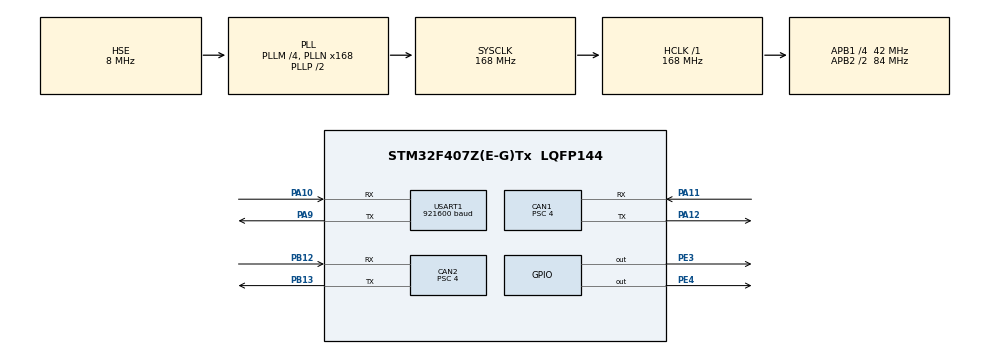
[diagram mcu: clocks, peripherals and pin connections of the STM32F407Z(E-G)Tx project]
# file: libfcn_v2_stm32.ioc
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CAN1.BS1=CAN_BS1_6TQ
CAN1.BS2=CAN_BS2_7TQ
CAN1.CalculateTimeQuantum=95.23809523809524
CAN1.Prescaler=4
CAN1.SJW=CAN_SJW_1TQ
CAN2.BS1=CAN_BS1_6TQ
CAN2.BS2=CAN_BS2_7TQ
CAN2.CalculateTimeQuantum=95.23809523809524
CAN2.Prescaler=4
Mcu.Family=STM32F4
Mcu.Name=STM32F407Z(E-G)Tx
Mcu.Package=LQFP144
NVIC.PriorityGroup=NVIC_PRIORITYGROUP_4
NVIC.TIM2_IRQn=true\:0\:0\:false\:false\:true\:false\:true
NVIC.TimeBase=TIM2_IRQn
NVIC.TimeBaseIP=TIM2
PA10.Mode=Asynchronous
PA10.Signal=USART1_RX
PA11.Mode=Master
PA11.Signal=CAN1_RX
PA12.Mode=Master
PA12.Signal=CAN1_TX
PA9.Mode=Asynchronous
PA9.Signal=USART1_TX
PB12.Mode=Slave
PB12.Signal=CAN2_RX
PB13.Mode=Slave
PB13.Signal=CAN2_TX
PC14-OSC32_IN.Mode=LSE-External-Oscillator
PC14-OSC32_IN.Signal=RCC_OSC32_IN
PC15-OSC32_OUT.Mode=LSE-External-Oscillator
PC15-OSC32_OUT.Signal=RCC_OSC32_OUT
PE3.GPIO_Speed=GPIO_SPEED_FREQ_VERY_HIGH
PE3.Signal=GPIO_Output
PE4.GPIO_Speed=GPIO_SPEED_FREQ_VERY_HIGH
PE4.Signal=GPIO_Output
PH0-OSC_IN.Mode=HSE-External-Oscillator
PH0-OSC_IN.Signal=RCC_OSC_IN
PH1-OSC_OUT.Mode=HSE-External-Oscillator
PH1-OSC_OUT.Signal=RCC_OSC_OUT
ProjectManager.HeapSize=0x200
ProjectManager.StackSize=0x400
ProjectManager.TargetToolchain=STM32CubeIDE
RCC.48MHZClocksFreq_Value=48000000
RCC.AHBFreq_Value=168000000
RCC.APB1CLKDivider=RCC_HCLK_DIV4
RCC.APB1Freq_Value=42000000
RCC.APB1TimFreq_Value=84000000
RCC.APB2CLKDivider=RCC_HCLK_DIV2
RCC.APB2Freq_Value=84000000
RCC.APB2TimFreq_Value=168000000
RCC.CortexFreq_Value=168000000
RCC.HCLKFreq_Value=168000000
RCC.HSE_VALUE=8000000
RCC.HSI_VALUE=16000000
RCC.PLLM=4
RCC.PLLN=168
RCC.PLLQ=7
RCC.PLLSourceVirtual=RCC_PLLSOURCE_HSE
RCC.SYSCLKFreq_VALUE=168000000
RCC.SYSCLKSource=RCC_SYSCLKSOURCE_PLLCLK
RCC.VCOOutputFreq_Value=336000000
USART1.BaudRate=921600
USART1.VirtualMode=VM_ASYNC
VP_CRC_VS_CRC.Mode=CRC_Activate
VP_RNG_VS_RNG.Mode=RNG_Activate
VP_SYS_VS_tim2.Mode=TIM2
board=custom

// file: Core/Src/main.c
/* USER CODE BEGIN Header */
/**
  ******************************************************************************
  * @file           : main.c
  * @brief          : Main program body
  ******************************************************************************
  * @attention
  *
  * <h2><center>&copy; Copyright (c) 2020 STMicroelectronics.
  * All rights reserved.</center></h2>
  *
  * This software component is licensed by ST under BSD 3-Clause license,
  * the "License"; You may not use this file except in compliance with the
  * License. You may obtain a copy of the License at:
  *                        opensource.org/licenses/BSD-3-Clause
  *
  ******************************************************************************
  */
/* USER CODE END Header */
#include "main.h"

/* USER CODE BEGIN Includes */
#include "../../User/UserTask.h"
/* USER CODE END Includes */

CAN_HandleTypeDef hcan1;
CAN_HandleTypeDef hcan2;

CRC_HandleTypeDef hcrc;

RNG_HandleTypeDef hrng;

UART_HandleTypeDef huart1;

void SystemClock_Config(void);
static void MX_GPIO_Init(void);
static void MX_USART1_UART_Init(void);
static void MX_CAN1_Init(void);
static void MX_CAN2_Init(void);
static void MX_CRC_Init(void);
static void MX_RNG_Init(void);

int main(void)
{

  /* MCU Configuration--------------------------------------------------------*/

  /* Reset of all peripherals, Initializes the Flash interface and the Systick. */
  HAL_Init();

  /* Configure the system clock */
  SystemClock_Config();

  /* Initialize all configured peripherals */
  MX_GPIO_Init();
  MX_USART1_UART_Init();
  MX_CAN1_Init();
  MX_CAN2_Init();
  MX_CRC_Init();
  MX_RNG_Init();
  /* USER CODE BEGIN 2 */
  BootTaskAfterHwInit();
  /* USER CODE END 2 */

  /* Infinite loop */
  while (1)
  {

    /* USER CODE BEGIN 3 */
	  MainLoopTask();
  }
  /* USER CODE END 3 */
}

void SystemClock_Config(void)
{
  RCC_OscInitTypeDef RCC_OscInitStruct = {0};
  RCC_ClkInitTypeDef RCC_ClkInitStruct = {0};

  /** Configure the main internal regulator output voltage
  */
  __HAL_RCC_PWR_CLK_ENABLE();
  __HAL_PWR_VOLTAGESCALING_CONFIG(PWR_REGULATOR_VOLTAGE_SCALE1);
  /** Initializes the RCC Oscillators according to the specified parameters
  * in the RCC_OscInitTypeDef structure.
  */
  RCC_OscInitStruct.OscillatorType = RCC_OSCILLATORTYPE_HSE;
  RCC_OscInitStruct.HSEState = RCC_HSE_ON;
  RCC_OscInitStruct.PLL.PLLState = RCC_PLL_ON;
  RCC_OscInitStruct.PLL.PLLSource = RCC_PLLSOURCE_HSE;
  RCC_OscInitStruct.PLL.PLLM = 4;
  RCC_OscInitStruct.PLL.PLLN = 168;
  RCC_OscInitStruct.PLL.PLLP = RCC_PLLP_DIV2;
  RCC_OscInitStruct.PLL.PLLQ = 7;
  if (HAL_RCC_OscConfig(&RCC_OscInitStruct) != HAL_OK)
  {
    Error_Handler();
  }
  /** Initializes the CPU, AHB and APB buses clocks
  */
  RCC_ClkInitStruct.ClockType = RCC_CLOCKTYPE_HCLK|RCC_CLOCKTYPE_SYSCLK
                              |RCC_CLOCKTYPE_PCLK1|RCC_CLOCKTYPE_PCLK2;
  RCC_ClkInitStruct.SYSCLKSource = RCC_SYSCLKSOURCE_PLLCLK;
  RCC_ClkInitStruct.AHBCLKDivider = RCC_SYSCLK_DIV1;
  RCC_ClkInitStruct.APB1CLKDivider = RCC_HCLK_DIV4;
  RCC_ClkInitStruct.APB2CLKDivider = RCC_HCLK_DIV2;

  if (HAL_RCC_ClockConfig(&RCC_ClkInitStruct, FLASH_LATENCY_5) != HAL_OK)
  {
    Error_Handler();
  }
}

static void MX_CAN1_Init(void)
{

  hcan1.Instance = CAN1;
  hcan1.Init.Prescaler = 4;
  hcan1.Init.Mode = CAN_MODE_NORMAL;
  hcan1.Init.SyncJumpWidth = CAN_SJW_1TQ;
  hcan1.Init.TimeSeg1 = CAN_BS1_6TQ;
  hcan1.Init.TimeSeg2 = CAN_BS2_7TQ;
  hcan1.Init.TimeTriggeredMode = DISABLE;
  hcan1.Init.AutoBusOff = DISABLE;
  hcan1.Init.AutoWakeUp = DISABLE;
  hcan1.Init.AutoRetransmission = DISABLE;
  hcan1.Init.ReceiveFifoLocked = DISABLE;
  hcan1.Init.TransmitFifoPriority = DISABLE;
  if (HAL_CAN_Init(&hcan1) != HAL_OK)
  {
    Error_Handler();
  }

}

static void MX_CAN2_Init(void)
{

  hcan2.Instance = CAN2;
  hcan2.Init.Prescaler = 4;
  hcan2.Init.Mode = CAN_MODE_NORMAL;
  hcan2.Init.SyncJumpWidth = CAN_SJW_1TQ;
  hcan2.Init.TimeSeg1 = CAN_BS1_6TQ;
  hcan2.Init.TimeSeg2 = CAN_BS2_7TQ;
  hcan2.Init.TimeTriggeredMode = DISABLE;
  hcan2.Init.AutoBusOff = DISABLE;
  hcan2.Init.AutoWakeUp = DISABLE;
  hcan2.Init.AutoRetransmission = DISABLE;
  hcan2.Init.ReceiveFifoLocked = DISABLE;
  hcan2.Init.TransmitFifoPriority = DISABLE;
  if (HAL_CAN_Init(&hcan2) != HAL_OK)
  {
    Error_Handler();
  }

}

static void MX_CRC_Init(void)
{

  hcrc.Instance = CRC;
  if (HAL_CRC_Init(&hcrc) != HAL_OK)
  {
    Error_Handler();
  }

}

static void MX_RNG_Init(void)
{

  hrng.Instance = RNG;
  if (HAL_RNG_Init(&hrng) != HAL_OK)
  {
    Error_Handler();
  }

}

static void MX_USART1_UART_Init(void)
{

  huart1.Instance = USART1;
  huart1.Init.BaudRate = 921600;
  huart1.Init.WordLength = UART_WORDLENGTH_8B;
  huart1.Init.StopBits = UART_STOPBITS_1;
  huart1.Init.Parity = UART_PARITY_NONE;
  huart1.Init.Mode = UART_MODE_TX_RX;
  huart1.Init.HwFlowCtl = UART_HWCONTROL_NONE;
  huart1.Init.OverSampling = UART_OVERSAMPLING_16;
  if (HAL_UART_Init(&huart1) != HAL_OK)
  {
    Error_Handler();
  }

}

static void MX_GPIO_Init(void)
{
  GPIO_InitTypeDef GPIO_InitStruct = {0};

  /* GPIO Ports Clock Enable */
  __HAL_RCC_GPIOE_CLK_ENABLE();
  __HAL_RCC_GPIOC_CLK_ENABLE();
  __HAL_RCC_GPIOH_CLK_ENABLE();
  __HAL_RCC_GPIOB_CLK_ENABLE();
  __HAL_RCC_GPIOA_CLK_ENABLE();

  /*Configure GPIO pin Output Level */
  HAL_GPIO_WritePin(GPIOE, GPIO_PIN_3|GPIO_PIN_4, GPIO_PIN_RESET);

  /*Configure GPIO pins : PE3 PE4 */
  GPIO_InitStruct.Pin = GPIO_PIN_3|GPIO_PIN_4;
  GPIO_InitStruct.Mode = GPIO_MODE_OUTPUT_PP;
  GPIO_InitStruct.Pull = GPIO_NOPULL;
  GPIO_InitStruct.Speed = GPIO_SPEED_FREQ_VERY_HIGH;
  HAL_GPIO_Init(GPIOE, &GPIO_InitStruct);

}

void HAL_TIM_PeriodElapsedCallback(TIM_HandleTypeDef *htim)
{
  if (htim->Instance == TIM2) {
    HAL_IncTick();
  }
}

void Error_Handler(void)
{
}

/************************ (C) COPYRIGHT STMicroelectronics *****END OF FILE****/
